# RL7005_IP_SVD register map
Vendor: Realtek
Registers are 32-bit, read-write, reset 0x0 unless marked. A register's access mark holds for its fields unless they carry their own. Offsets are from the block's base; [hi:lo] are bit positions; {n}, {i} and the like mark numbered series; <NAME> marks a mode.

## PAGE7
Base 0x40000000
0x700 REG_MACID1
  [31:0] BIT_MACID1_0 — MAC Identification Number Register for port 1
0x704 REG_MACID1_1
  [15:0] BIT_MACID1_1 — MAC Identification Number Register for port 1
0x708 REG_BSSID1
  [31:0] BIT_BSSID1_0 — Basic Station Set Identification for port 1.
0x70C REG_BSSID1_1
  [15:0] BIT_BSSID1_1 — Basic Station Set Identification for port 1.
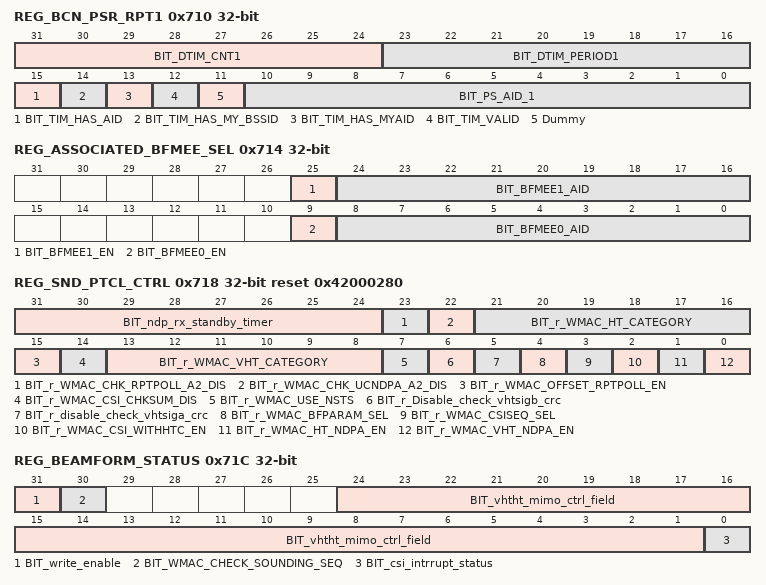
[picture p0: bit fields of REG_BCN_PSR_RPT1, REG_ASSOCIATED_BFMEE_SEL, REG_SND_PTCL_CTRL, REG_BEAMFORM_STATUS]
0x710 REG_BCN_PSR_RPT1 access per field
  [31:24] BIT_DTIM_CNT1 ro — DTIM count
  [23:16] BIT_DTIM_PERIOD1 ro — DTIM Period
  [15] BIT_TIM_HAS_AID ro — indicate BC/MC packets are buffered at the AP or transimited BSSID
  [14] BIT_TIM_HAS_MY_BSSID ro — indicate BC/MC packets are buffered at nontransmitted BSSID, sw need to check corresponding dtim count field in multiple bssid index field
  [13] BIT_TIM_HAS_MYAID ro — my aid in the virtual bitmap is set
  [12] BIT_TIM_VALID ro — when set to 1 , indicate tim report valid
  [11] Dummy rw
  [10:0] BIT_PS_AID_1 rw — AID1 for MACID1
0x714 REG_ASSOCIATED_BFMEE_SEL
  [25] BIT_BFMEE1_EN — If enabled, NDPA would be sent to beamformee1.
  [24:16] BIT_BFMEE1_AID — P_AID of the target beamformee1
  [9] BIT_BFMEE0_EN — If enabled, NDPA would be sent to beamformee0.
  [8:0] BIT_BFMEE0_AID — P_AID of the target beamformee0
0x718 REG_SND_PTCL_CTRL reset 0x42000280
  [31:24] BIT_ndp_rx_standby_timer — A timeout value for MAC to leave NDP_Rx_standby_state and go back to normal Rx mode. (unit: 2us)
  [23] BIT_r_WMAC_CHK_RPTPOLL_A2_DIS — 1: For any A1-matched BF Rpt Poll, send back VHT-CB 0: If A1-matched BF Rpt Poll's A2 fails to match the previous receiving NDPA's A2, do not send VHT-CB
  [22] BIT_r_WMAC_CHK_UCNDPA_A2_DIS — 0: If A1-matched NDPA's A2 fails to match 0x6E4 or 0x6EC, use default csi parameter 1: For any receiving A1-matched NDPA, use 0x6F4[11:0] as csi parameter
  [21:16] BIT_r_WMAC_HT_CATEGORY — csi report offset for ht mode
  [15] BIT_r_WMAC_OFFSET_RPTPOLL_EN — 1: If previous Tx pkt is BF Rpt Poll or VHT NDP, use vht csi start offset; otherwise ht csi start offset 0: If previous Tx pkt is vht rate, use vht csi start offset; otherwise ht csi start offset
  [14] BIT_r_WMAC_CSI_CHKSUM_DIS — 1:Disable check 16bit checksum value of csi report from BB 0:Enable check 16bit checksum value of csi report from BB
  [13:8] BIT_r_WMAC_VHT_CATEGORY — used as csi report offset
  [7] BIT_r_WMAC_USE_NSTS — 1: use Nsts as Nr, 0: use register value as Nr
  [6] BIT_r_Disable_check_vhtsigb_crc — 1: disable, 0: enable
  [5] BIT_r_disable_check_vhtsiga_crc — 1: disable, 0: enable
  [4] BIT_r_WMAC_BFPARAM_SEL — 1: use beamforming nc/nr/ng parameter from register 0x6F4 0: use beamforming nc/nr/ng parameter from tx report buffer
  [3] BIT_r_WMAC_CSISEQ_SEL — By which the sequence number of CSI frame is controlled 1: non-QoS SEQ number 0: counter
  [2] BIT_r_WMAC_CSI_WITHHTC_EN — Set to 1, CSI frame would carry HTC in MAC header.
  [1] BIT_r_WMAC_HT_NDPA_EN — Set to 1, MAC would inform BB of preparing to receive NDP if the received NDP Announcement MPDU is valid.
  [0] BIT_r_WMAC_VHT_NDPA_EN — Set to 1, MAC would inform BB of preparing to receive NDP if the received NDPA is valid.
0x71C REG_BEAMFORM_STATUS access per field
  [31] BIT_write_enable ro — Access flag. '0' for read. '1' for write, 0x72C[15:0] must be sett before this bit is set
  [30] BIT_WMAC_CHECK_SOUNDING_SEQ rw — Set to 1,MAC would check sounding sequence number of received CSI report and transmitted NDPA
  [24:1] BIT_vhtht_mimo_ctrl_field ro — when 'read': [24:1]: currently received VHT MIMO Control field or [16:1]: currently received HT MIMO Control field
  [0] BIT_csi_intrrupt_status ro — sounding status: '0': fail; '1': success;
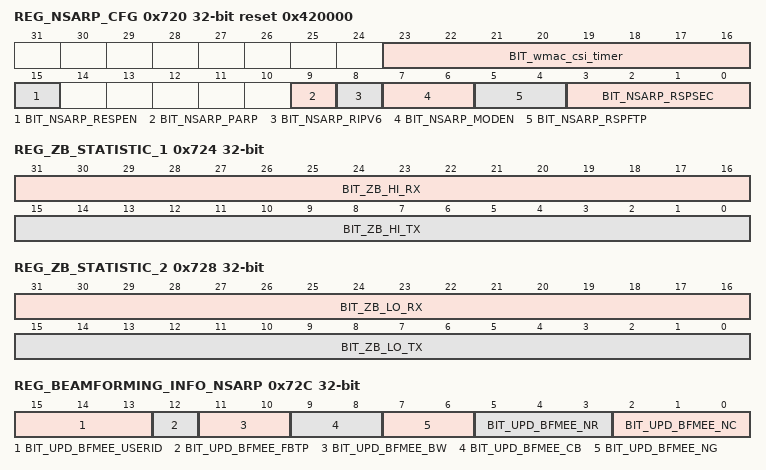
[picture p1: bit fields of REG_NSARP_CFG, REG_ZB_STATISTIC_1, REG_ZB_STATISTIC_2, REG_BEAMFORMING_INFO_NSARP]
0x720 REG_NSARP_CFG reset 0x420000
  [23:16] BIT_wmac_csi_timer — A timeout value for csi_wait_poll. (unit: 512us)
  [15] BIT_NSARP_RESPEN — NAARP parser enable
  [9] BIT_NSARP_PARP — when set to 1, reject ARP
  [8] BIT_NSARP_RIPV6 — when set to 1, reject IPV6
  [7:6] BIT_NSARP_MODEN — r_WMAC_NSARP_MODEN[0]: when set to 1, enable arp request; r_WMAC_NSARP_MODEN[1]: when set to 1, enable ipv6 request;
  [5:4] BIT_NSARP_RSPFTP — used to select Response_type and TID
  [3:0] BIT_NSARP_RSPSEC — select response packet security type
0x724 REG_ZB_STATISTIC_1 ro
  [31:16] BIT_ZB_HI_RX — for statistic
  [15:0] BIT_ZB_HI_TX
0x728 REG_ZB_STATISTIC_2 ro
  [31:16] BIT_ZB_LO_RX — for statistic
  [15:0] BIT_ZB_LO_TX
0x72C REG_BEAMFORMING_INFO_NSARP
  [15:13] BIT_UPD_BFMEE_USERID — Select BFMEE User ID
  [12] BIT_UPD_BFMEE_FBTP — Feedback Type(B11) of VHT MIMO Control field, HT is no used
  [11:10] BIT_UPD_BFMEE_BW — Channel Width of VHT MIMO control field (B7-6) and (B4) when HT mode
  [9:8] BIT_UPD_BFMEE_CB — Codebook Information of MIMO control field [8] for VHT (B10) and (B10-9) when HT mode
  [7:6] BIT_UPD_BFMEE_NG — Grouping of MIMO control field [7:6] for VHT (B9-8) and (B6-5) when HT mode
  [5:3] BIT_UPD_BFMEE_NR — Nr Index of MIMO control field [5:3] for VHT (B5-3) ,[4:3] for HT mode (B3-2)
  [2:0] BIT_UPD_BFMEE_NC — Nc Index of MIMO control field [2:0] for VHT (B2-0) , [1:0] for HT mode (B1-0)
{0x730+4i} REG_IPV6_{i} (i=0..3)
  [31:0] BIT_IPV6_MYIPAD_{i}
0x740 REG_ZB_COEX_TABLE_1
  [31:0] BIT_ZB_COEX_TABLE_1 — coexistence table between WLAN and Zigbee, selected by BIT_COEX_TABLE_SEL = 0
0x744 REG_ZB_COEX_TABLE_2
  [31:0] BIT_ZB_COEX_TABLE_2 — coexistence table between WLAN and Zigbee, selected by BIT_COEX_TABLE_SEL = 1
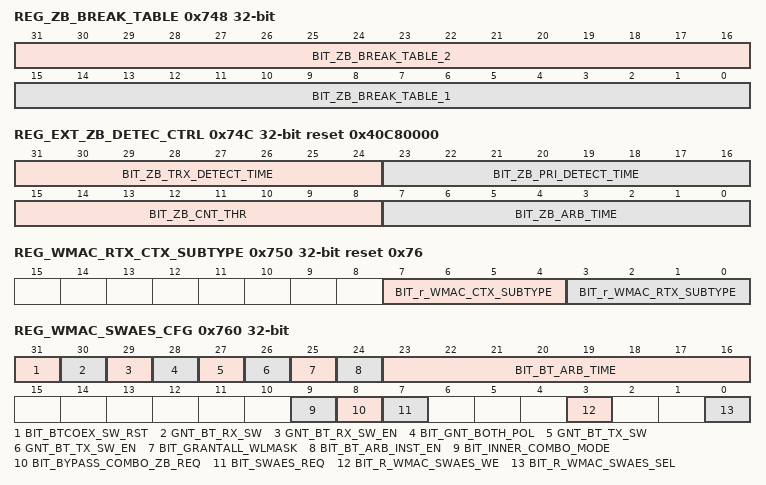
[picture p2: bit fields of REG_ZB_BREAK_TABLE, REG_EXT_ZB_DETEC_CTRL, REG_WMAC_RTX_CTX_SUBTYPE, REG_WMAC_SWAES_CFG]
0x748 REG_ZB_BREAK_TABLE
  [31:16] BIT_ZB_BREAK_TABLE_2 — Table used to break ZB activity, when new WLAN request is coming and ZB is on transmitting or receiving
  [15:0] BIT_ZB_BREAK_TABLE_1 — Table used to break WLAN activity, when new ZB request is coming and WLAN is on transmitting or receiving
0x74C REG_EXT_ZB_DETEC_CTRL reset 0x40C80000
  [31:24] BIT_ZB_TRX_DETECT_TIME — Valid if BIT_ZIGBEE_MODE = 1 & BIT_EXT_ZIGBEE_MODE = 0 (external mode, directional PRIORITY) After ZB_PRI_DETECT_TIME duration, if ZB_PRIORITY is low or goes low during ZB_TRX_INIT_DETECT_TIME, Zigbee will receive packets; otherwise, if ZG_PRIORITY is high or goes high, ZB will TX data. Unit 1us.
  [23:16] BIT_ZB_PRI_DETECT_TIME — Valid if BIT_ZIGBEE_MODE = 1 & BIT_EXT_ZIGBEE_MODE = 0 (external mode, directional PRIORITY) After ZB_REQUEST asserting, if ZG_PRIORITY is asserted within this ZB_PRI_DETECT_TIME duration, ZG will initiate high priority activities; otherwise, if ZB_PRIORITY is not asserted within this duration, it would be low priority activities. Units 1us. (0-255us)
  [15:8] BIT_ZB_CNT_THR — ZB count threshold, unit: us
  [7:0] BIT_ZB_ARB_TIME — 8 bit timer register : Arbitration window of ZB trx request (unit: us)
0x750 REG_WMAC_RTX_CTX_SUBTYPE reset 0x76
  [7:4] BIT_r_WMAC_CTX_SUBTYPE, [3:0] BIT_r_WMAC_RTX_SUBTYPE
{0x750+4i} REG_WMAC_RTX_SWAES_RD_{i} ro (i=1..3)
  [31:0] wmac_swaes_rd_{i-1}
0x760 REG_WMAC_SWAES_CFG access per field
  [31] BIT_BTCOEX_SW_RST rw
  [30] GNT_BT_RX_SW rw — SW control GNT_BT_RX
  [29] GNT_BT_RX_SW_EN rw — SW control GNT_BT_RX enable
  [28] BIT_GNT_BOTH_POL rw — grant both choose GNT_BT polarity: 0 : deassert GNT_BT signal as PTA grant both WiFI and BT. 1 : assert GNT_BT signal as PTA grant both WiFi and BT.
  [27] GNT_BT_TX_SW rw — SW control GNT_BT_TX
  [26] GNT_BT_TX_SW_EN rw — SW control GNT_BT_TX enable
  [25] BIT_GRANTALL_WLMASK rw — 0: WLAN_ACT to BT is always 0
  [24] BIT_BT_ARB_INST_EN rw — 1: enable GNT_BT_BYPASS_PRIORITY 0 : disable
  [23:16] BIT_BT_ARB_TIME rw — 8 bit timer register : Arbitration window of bt trx request ( in the unit of us)
  [9] BIT_INNER_COMBO_MODE rw — 1: RTK combo IP parser zb_request or bt_request,zb_request will use wl-zb coex table co-work with BIT_BYPASS_COMBO_ZB_REQ = 0
  [8] BIT_BYPASS_COMBO_ZB_REQ rw — 1: ignore zb flag from RTK combo IP 0: distinguish zb_request and bt_request from RTK combo IP
  [7] BIT_SWAES_REQ ro — software aes engine request polling
  [3] BIT_R_WMAC_SWAES_WE rw — Write enable of register ro_WMAC_SWAES_RD
  [0] BIT_R_WMAC_SWAES_SEL rw — When R_WMAC_SWAES_SEL =1,the content of register 0750-075F used to be aes engine data in or data out . When R_WMAC_SWAES_SEL =0, the content of register 0754-075F used to be aes engine security key
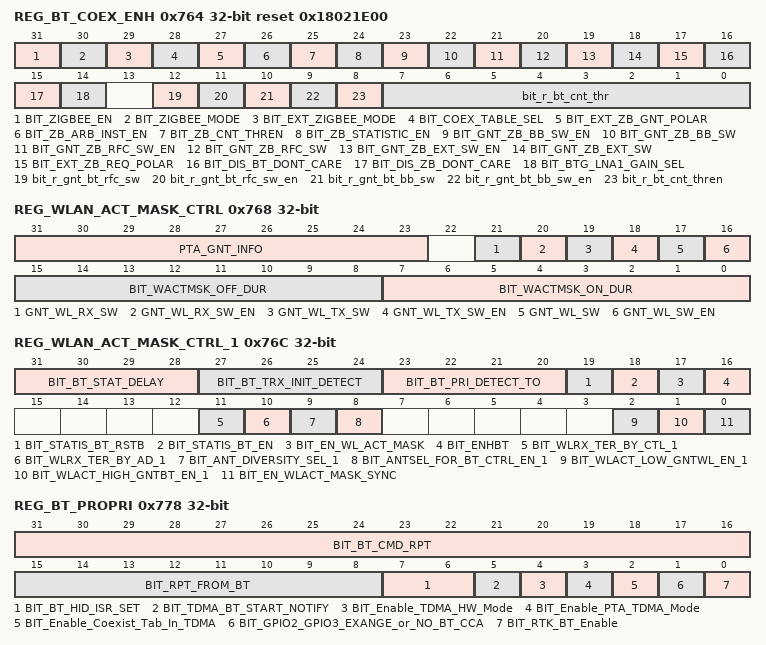
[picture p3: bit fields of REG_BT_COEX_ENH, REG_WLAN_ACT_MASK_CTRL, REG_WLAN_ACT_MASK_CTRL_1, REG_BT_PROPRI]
0x764 REG_BT_COEX_ENH reset 0x18021E00
  [31] BIT_ZIGBEE_EN — Enable ZigBee function
  [30] BIT_ZIGBEE_MODE — 0: SOC 1: external
  [29] BIT_EXT_ZIGBEE_MODE — The mode of external ZigBee 1: static PRIORITY 0: directional PRIORITY
  [28] BIT_COEX_TABLE_SEL — Select coexistence table for WLAN & ZB 0: BIT_COEX_TABLE_WL_ZB_1 1: BIT_COEX_TABLE_WL_ZB_2
  [27] BIT_EXT_ZB_GNT_POLAR — Select the polar of ZB_GRANT, for extarnal ZB 0: low active 1: high active
  [26] BIT_ZB_ARB_INST_EN — 1: enable the time limit of ZigBee request (zb_pri | zb_rx | zb_tx), PTA is valid during ( <=BIT_ZB_ARB_TIME) 0: disable Co-work with BIT_ZB_ARB_TIME
  [25] BIT_ZB_CNT_THREN — ZB count threshold enable, for statistics co-work with BIT_ZB_CNT_THR
  [24] BIT_ZB_STATISTIC_EN — enable statistic of ZB
  [23] BIT_GNT_ZB_BB_SW_EN — Enable SW control gnt_zb_bb
  [22] BIT_GNT_ZB_BB_SW — SW value
  [21] BIT_GNT_ZB_RFC_SW_EN — Enable SW control gnt_zb_rfc
  [20] BIT_GNT_ZB_RFC_SW — SW value
  [19] BIT_GNT_ZB_EXT_SW_EN — Enable SW control gnt_zb_o of external ZigBee
  [18] BIT_GNT_ZB_EXT_SW — SW value, external ZigBee
  [17] BIT_EXT_ZB_REQ_POLAR — Select the polar of ZB_REQUEST, for static mode external ZB 0: low active 1: high active
  [16] BIT_DIS_BT_DONT_CARE — 1: break table of BT & WL can be all "1" 0: break table of BT & WL cannot be all "1"
  [15] BIT_DIS_ZB_DONT_CARE — 1: break table of ZB & WL can be all "1" 0: break table of ZB & WL cannot be all "1"
  [14] BIT_BTG_LNA1_GAIN_SEL — control by Driver 0: mask for WL 1: original BTG
  [12] bit_r_gnt_bt_rfc_sw — SW control BT RF
  [11] bit_r_gnt_bt_rfc_sw_en — SW control BT RF enable
  [10] bit_r_gnt_bt_bb_sw — SW control BT baseband
  [9] bit_r_gnt_bt_bb_sw_en — SW control BT baseband enable
  [8] bit_r_bt_cnt_thren — BT count threshold enable
  [7:0] bit_r_bt_cnt_thr — BT count threshold
0x768 REG_WLAN_ACT_MASK_CTRL access per field
  [31:23] PTA_GNT_INFO ro — [0]: gnt_wl [1]: gnt_bt_bb [2]: gnt_bt_rfc [3]: gnt_zb_bb [4]: gnt_zb_rfc [5]: gnt_wl_tx [6]: gnt_wl_rx [7]: gnt_bt_tx [8]: gnt_bt_rx
  [21] GNT_WL_RX_SW rw — SW control GNT_WL_RX
  [20] GNT_WL_RX_SW_EN rw — SW control GNT_WL_RX enable
  [19] GNT_WL_TX_SW rw — SW control GNT_WL_TX
  [18] GNT_WL_TX_SW_EN rw — SW control GNT_WL_TX enable
  [17] GNT_WL_SW rw — SW control GNT_WL
  [16] GNT_WL_SW_EN rw — SW control GNT_WL enable
  [15:8] BIT_WACTMSK_OFF_DUR rw — WLAN will reserve channel for BT during MASK OFF duration. Unit 0.625ms
  [7:0] BIT_WACTMSK_ON_DUR rw — WLAN can block BT during MASK On duration. Unit 0.625ms
0x76C REG_WLAN_ACT_MASK_CTRL_1
  [31:28] BIT_BT_STAT_DELAY — For CSR, BT_PRI and BT_STAT go high form low at the same time. Thus, BT_STAT need delay BT_STAT_DELAY time to trigger hardware. Unit: 1us
  [27:24] BIT_BT_TRX_INIT_DETECT — After BT_PRI asserting for BT_TRX_INIT_DETECT us, if BT_STAT is low, then BT will receive packets; otherwise, if BT goes high, BT will TX data. Unit 4us.
  [23:20] BIT_BT_PRI_DETECT_TO — After BT_PRI asserting, if BT_STAT is asserted within this TO duration, BT will initiate high priority activities; otherwise, if BT_STAT is not asserted within this duration, it would be low priority activities. Units 1us.
  [19] BIT_STATIS_BT_RSTB — clear BT static info
  [18] BIT_STATIS_BT_EN — When this bit is set, the BT_ACT_STATISTICS counters starts counting
  [17] BIT_EN_WL_ACT_MASK — Enable WLAN_ACT Mask Function (related to 0x768h-0x76Dh)
  [16] BIT_ENHBT — Enable Enhanced BT Interface (we suggest to use with BT mode 2)
  [11] BIT_WLRX_TER_BY_CTL_1 — When wlan receive a control packet without fit address, whether the signal indicating wlan rx can be terminated as soon as the address check finish is not only controlled by r_WLRX_TER_BY_AD, but also should be refereed to this bit. 1: enable; 0: disable
  [10] BIT_WLRX_TER_BY_AD_1 — When wlan receive the packet without fit address, the signal indicating wlan rx can be terminated as soon as the address check finish. This feature can be enabled by this bit. 1: en
  [9] BIT_ANT_DIVERSITY_SEL_1 — Antenna diversity for 2 antenna mode: MAC_ANT_SEL = GNT_BT ^ ANT_DIVERDITY_SEL
  [8] BIT_ANTSEL_FOR_BT_CTRL_EN_1 — Enable the control of antenna selection through GNT_BT: GNT_BT=1: ANT_SEL for BT device; GNT_BT=0: ANT_SEL for WL device.
  [2] BIT_WLACT_LOW_GNTWL_EN_1 — When WLACT_LOW_GNTWL_EN = 1, the TRX of WLAN are blocked according to the BTCOEX table arbitration during MASK OFF duration. WLACT_LOW_GNTWL_EN = 0, the TRX of WLAN are paused during MASK OFF duration..
  [1] BIT_WLACT_HIGH_GNTBT_EN_1 — When WLACT_HIGH_GNTBT_EN = 1, the TRX of WLAN are blocked according to the BTCOEX table arbitration during MASK ON duration. When WLACT_HIGH_ GNTBT_EN = 0, the TRX of WLAN are not paused during MASK OFF duration.
  [0] BIT_EN_WLACT_MASK_SYNC — When NAV update is beyond this value, then NAV update is aborted. When this field is 0x00, NAV_UPPER function is disable. The unit is 128us.
0x770 REG_BT_ENHANCED_CTRL0 ro
  [31:0] BIT_STATIS_BT_31_0
0x774 REG_BT_ENHANCED_CTRL1 ro
  [31:0] BIT_STATIS_BT_63_32
0x778 REG_BT_PROPRI access per field
  [31:16] BIT_BT_CMD_RPT ro
  [15:8] BIT_RPT_FROM_BT ro
  [7:6] BIT_BT_HID_ISR_SET rw — When EN_BT_PROFILE_OR_HID is set "1", hardware also need to check this value to trigger an interrupt. 0: default, TX and RX 1: TX 2: RX 3: Reserved
  [5] BIT_TDMA_BT_START_NOTIFY rw — When the control of TDMA mode is firmware and firmware also receive signal that NULL packet for BT had sent, firmware can fill this bit to notify HW PTA to pull WLAN_ACT to low and the interval is Tbt
  [4] BIT_Enable_TDMA_HW_Mode rw — 0: default, PTA TDMA mode is hardware mode. 1: enable firmware mode.
  [3] BIT_Enable_PTA_TDMA_Mode rw — 0: default, disable PTA TDMA mode 1: enable TDMA mode: a. WLAN_ACT default is high. b. Hardware mode: When NULL packet for BT had sent, hardware will notify PTA to start TDMA mode. Firmware mode: When NULL packet for BT had sent, hardware will trigger an interrupt to notify firmware. Then, firmware need to set TDMA_BT_START_NOTIFY to notify PTA to start TDMA mode.
  [2] BIT_Enable_Coexist_Tab_In_TDMA rw — 0: default, no matter which WLAN_ACT is high or low, PTA doesn't execute co-exist table scheme 1: enable, When WLAN_ACT is high, PTA execute xo-exist table scheme
  [1] BIT_GPIO2_GPIO3_EXANGE_or_NO_BT_CCA rw — Enable GPIO2 and GPIO3 exchange. (Note: need to enable mode2 and enhance 3 wire) If Enable RTK BT mode, set this bit to 1 to disable granting to BT device when arbitration
  [0] BIT_RTK_BT_Enable rw — Enable RTK BT mode
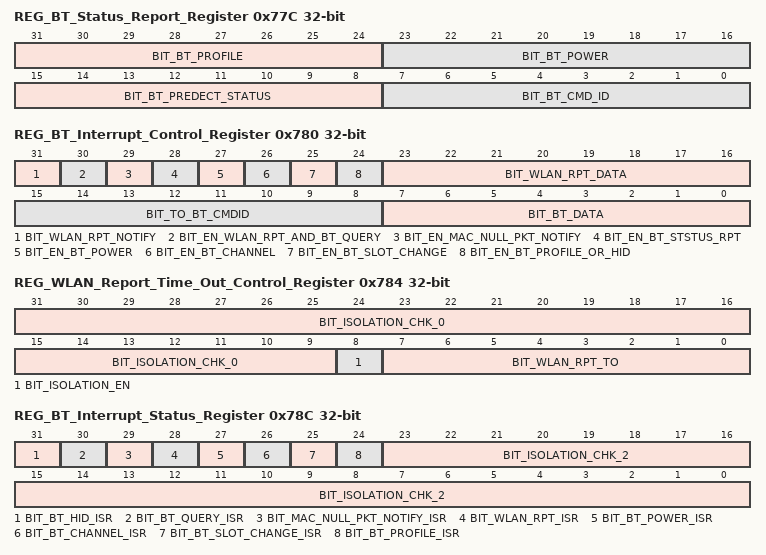
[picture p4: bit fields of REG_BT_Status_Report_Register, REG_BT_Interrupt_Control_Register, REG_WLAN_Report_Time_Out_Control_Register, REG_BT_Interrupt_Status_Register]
0x77C REG_BT_Status_Report_Register ro
  [31:24] BIT_BT_PROFILE — When WLAN received CMD_ID 0x3, it will recorder to this.
  [23:16] BIT_BT_POWER — When WLAN received CMD_ID 0x2, it will recorder to this
  [15:8] BIT_BT_PREDECT_STATUS — When WLAN received CMD_ID 0x0, it will recorder to this
  [7:0] BIT_BT_CMD_ID — command information from BT
0x780 REG_BT_Interrupt_Control_Register access per field
  [31] BIT_WLAN_RPT_NOTIFY rw — When firmware had prepared packet to send to BT, it need to set this bit to notify hardware that it can transmit. 0: There isn't a valid packet in register" WLAN_RPT_ PKT". 1: There is a valid packet in register" WLAN_RPT_ PKT".
  [30] BIT_EN_WLAN_RPT_AND_BT_QUERY rw — Enable two interrupt: 1) PTA sent the report packet successfully 2) PTA sent a query packet 0: Disable 1: Enable
  [29] BIT_EN_MAC_NULL_PKT_NOTIFY rw — When MAC had sent NULL packet for BT and firmware also set nav_for_bt bit, hardware triggers an interrupt to notify firmware. 0: Disable 1: Enable
  [28] BIT_EN_BT_STSTUS_RPT rw — When WLAN receive cmd_id "0", hardware trigger an interrupt to notify firmware. 0: Disable 1: Enable
  [27] BIT_EN_BT_POWER rw — When WLAN received the packet including BT Power and check register "BT_STATUS_RPT", if data contents aren't the same, hardware can trigger an interrupt to notify firmware. 0: Disable 1: Enable
  [26] BIT_EN_BT_CHANNEL rw — When WLAN received the packet including BT channel number, hardware can trigger an interrupt to notify firmware. 0: Disable 1: Enable
  [25] BIT_EN_BT_SLOT_CHANGE rw — When WLAN received the packet including that BT had multi-slots, hardware can trigger an interrupt to notify firmware. 0: Disable 1: Enable
  [24] BIT_EN_BT_PROFILE_OR_HID rw — Enable two interrupt 1) When WLAN received the packet including that WLAN specific profile and check register "BT_STATUS_RPT", if data contents aren't the same, hardware can trigger an interrupt to notify firmware. 2) When WLAN received the report packet including HID information, hardware will trigger an interrupt to notify firmware. 0: Disable 1: Enable
  [23:16] BIT_WLAN_RPT_DATA rw — Data contents, When the report packet had sent, hardware will clear this register.
  [15:8] BIT_TO_BT_CMDID rw — Command id: 0x80~FF
  [7:0] BIT_BT_DATA ro — When WLAN received the packet BT sent, hardware will place data to this register in addition to CMD_ID 0x0 ~ 0x3.
0x784 REG_WLAN_Report_Time_Out_Control_Register
  [31:9] BIT_ISOLATION_CHK_0 — 0: leave PTA 1: enter PTA
  [8] BIT_ISOLATION_EN — Isolation table enable bit. 0: disable 1: enable
  [7:0] BIT_WLAN_RPT_TO — When WLANＨW received query packet, HW timer counts. If timer equals to WLAN_RPT_TO and HW can"t send packet, it will give up query packet at this time. When BT sent another query packet, WLAN HW need to send the previous packet and it shouldn't trigger an interrupt to firmware. Unit: 4us.
0x788 REG_BT_Isolation_Table_Register_Register_1
  [31:0] BIT_ISOLATION_CHK_1 — 0: leave PTA 1: enter PTA
0x78C REG_BT_Interrupt_Status_Register access per field
  [31] BIT_BT_HID_ISR ro — When WLAN received the report packet including HID information, hardware will trigger an interrupt to notify firmware
  [30] BIT_BT_QUERY_ISR ro — When WLAN received a query packet, hardware triggers an interrupt to notify firmware
  [29] BIT_MAC_NULL_PKT_NOTIFY_ISR ro — When MAC had sent NULL packet for BT and firmware also set nav_for_bt bit, hardware triggers an interrupt to notify firmware
  [28] BIT_WLAN_RPT_ISR ro — When PTA sent the report packet successfully, hardware triggers an interrupt to notify firmware.
  [27] BIT_BT_POWER_ISR ro — When WLAN received the packet including BT Power and check register "BT_STATUS_RPT", if data contents aren't the same, hardware can trigger an interrupt to notify firmware
  [26] BIT_BT_CHANNEL_ISR ro — When WLAN received the packet including BT channel number, hardware can trigger an interrupt to notify firmware.
  [25] BIT_BT_SLOT_CHANGE_ISR ro — When WLAN received the packet including that BT had multi-slots, hardware can trigger an interrupt to notify firmware
  [24] BIT_BT_PROFILE_ISR ro — When WLAN received the packet including that WLAN specific profile and check register "BT_STATUS_RPT", if data contents aren't the same, hardware can trigger an interrupt to notify firmware.
  [23:0] BIT_ISOLATION_CHK_2 rw — 0: leave PTA 1: enter PTA
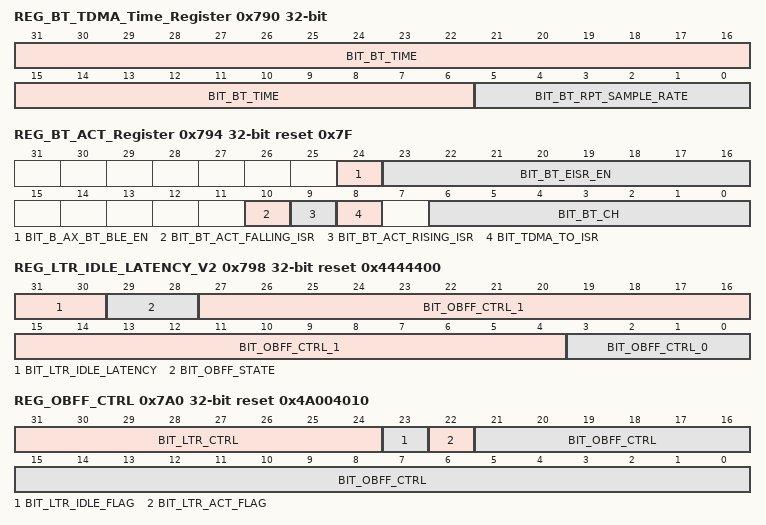
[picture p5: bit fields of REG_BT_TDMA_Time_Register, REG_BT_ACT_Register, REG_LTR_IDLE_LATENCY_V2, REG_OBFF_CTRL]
0x790 REG_BT_TDMA_Time_Register
  [31:6] BIT_BT_TIME — The time is that WLAN_ACT is low. Unit: us
  [5:0] BIT_BT_RPT_SAMPLE_RATE — When wifi detected the raising edge of BT report packet, wifi need to counter BT_RPT_SAMPLE_RATE. Then hw could detect which is high or low. Uint: 20 ns
0x794 REG_BT_ACT_Register access per field reset 0x7F
  [24] BIT_B_AX_BT_BLE_EN rw — Decide the GNT_BT_TX / RX 0: GNT_BT_TX = GNT_BT & BT_TX ; GNT_BT_RX = GNT_BT & BT_RX 1: GNT_BT_TX = GNT_BT & (BT_TX | BT_BLE) ; GNT_BT_RX = GNT_BT & (BT_RX | BT_BLE)
  [23:16] BIT_BT_EISR_EN rw — BT eisr enable
  [10] BIT_BT_ACT_FALLING_ISR ro — When BT_ACT signal is falling edge, it will trigger an interrupt.
  [9] BIT_BT_ACT_RISING_ISR ro — When BT_ACT signal is raising edge, it will trigger an interrupt
  [8] BIT_TDMA_TO_ISR ro — When BT_TIME expired, it will trigger an interrupt.
  [6:0] BIT_BT_CH ro — When hardware receive cm_id "1", it will recorder to this.
0x798 REG_LTR_IDLE_LATENCY_V2 access per field reset 0x4444400
  [31:30] BIT_LTR_IDLE_LATENCY rw — LTR idle latency.
  [29:28] BIT_OBFF_STATE ro
  [27:4] BIT_OBFF_CTRL_1 rw
  [3:0] BIT_OBFF_CTRL_0 ro
0x79C REG_LTR_ACTIVE_LATENCY_V2 reset 0x2030405
  [31:0] BIT_LTR_ACTIVE_LATENCY — LTR Active latency.
0x7A0 REG_OBFF_CTRL access per field reset 0x4A004010
  [31:24] BIT_LTR_CTRL rw, [23] BIT_LTR_IDLE_FLAG ro, [22] BIT_LTR_ACT_FLAG ro, [21:0] BIT_OBFF_CTRL rw
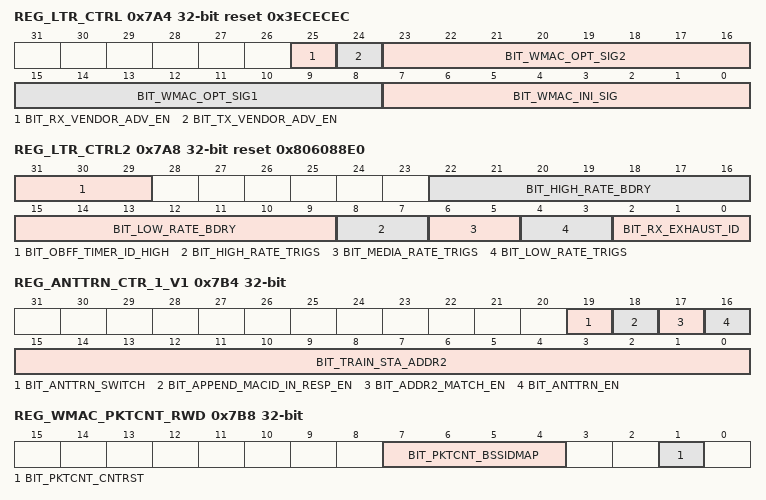
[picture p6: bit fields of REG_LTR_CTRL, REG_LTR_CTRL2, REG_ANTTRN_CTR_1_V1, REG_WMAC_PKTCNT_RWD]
0x7A4 REG_LTR_CTRL reset 0x3ECECEC
  [25] BIT_RX_VENDOR_ADV_EN — when set, rx vendor adv function is true
  [24] BIT_TX_VENDOR_ADV_EN — when set, tx vendor adv function is true
  [23:16] BIT_WMAC_OPT_SIG2 — For rx ofdm ppdu lsig signal filed check when rx vendor adv is true
  [15:8] BIT_WMAC_OPT_SIG1 — For rx ofdm ppdu lsig signal filed check when rx vendor adv is true
  [7:0] BIT_WMAC_INI_SIG — For rx ofdm ppdu lsig signal filed check when rx vendor adv is true
0x7A8 REG_LTR_CTRL2 reset 0x806088E0
  [31:29] BIT_OBFF_TIMER_ID_HIGH — When media rate rx packet in , delay rx dma timeout value index. 0: no delay,1: 12.8us; 2: 102.4us; 3: 204.8us; 4: 819.2 us; 5: 1.638ms; 6: 52ms; 7: always block until obff or cpu active window
  [22:16] BIT_HIGH_RATE_BDRY — High, media, low rate boundary
  [15:9] BIT_LOW_RATE_BDRY — High, media, low rate boundary
  [8:7] BIT_HIGH_RATE_TRIGS — High rate rx ltr trigger point select: 0 plcp ready;1: rx a1 latch OK; 2: fcs ready.
  [6:5] BIT_MEDIA_RATE_TRIGS — Media rate rx ltr trigger point select: 0 plcp ready;1: rx a1 latch OK; 2: fcs ready.
  [4:3] BIT_LOW_RATE_TRIGS — Low rate rx ltr trigger point select: 0 plcp ready;1: rx a1 latch OK; 2: fcs ready.
  [2:0] BIT_RX_EXHAUST_ID — When rx page less than this threshold, release obff block rx.
0x7B0 REG_ANTTRN_CTR_V1
  [31:0] BIT_TRAIN_STA_ADDR1 — The Address of the trained station. Only available when ADDR2_MATCH_EN = 1
0x7B4 REG_ANTTRN_CTR_1_V1
  [19] BIT_ANTTRN_SWITCH — Smart antenna use address cam or port register to search A2. 0:Use address cam 1:Use port register
  [18] BIT_APPEND_MACID_IN_RESP_EN — Whether to append MACID in the rx descriptor of rx response packet
  [17] BIT_ADDR2_MATCH_EN — Enable the comparison of ADDR2 for the rx packet..
  [16] BIT_ANTTRN_EN — Enable the antenna training function
  [15:0] BIT_TRAIN_STA_ADDR2 — The Address of the trained station. Only available when ADDR2_MATCH_EN = 1
0x7B8 REG_WMAC_PKTCNT_RWD ro
  [7:4] BIT_PKTCNT_BSSIDMAP — To decide this counter is for which MBSSID (16組), default : 0 for counter 0 1 for counter 1 2 for counter 2 3 for counter 3 4 for counter 4 5 for counter 5 6 for counter 6 7 for counter 7
  [1] BIT_PKTCNT_CNTRST — Write 1 to reset Counter after DRV read all counters , DRV set this bit and HW return 0 after reset
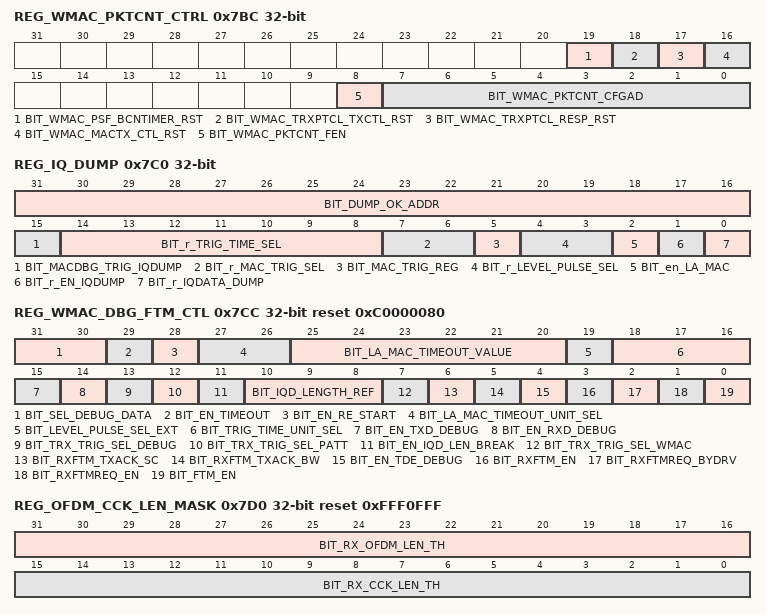
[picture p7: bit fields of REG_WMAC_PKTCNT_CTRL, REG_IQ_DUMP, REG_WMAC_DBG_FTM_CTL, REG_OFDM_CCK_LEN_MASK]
0x7BC REG_WMAC_PKTCNT_CTRL access per field
  [19] BIT_WMAC_PSF_BCNTIMER_RST wo — write pluse to reset fsm of wmac_psf_bcntimer
  [18] BIT_WMAC_TRXPTCL_TXCTL_RST wo — write pluse to reset fsm of wmac_trxptcl_txctl
  [17] BIT_WMAC_TRXPTCL_RESP_RST wo — write pluse to reset fsm of wmac_ptrxptcl_resp
  [16] BIT_WMAC_MACTX_CTL_RST wo — write pluse to reset fsm of ppdu control in mactx_ctl
  [8] BIT_WMAC_PKTCNT_FEN rw — Packet counter function enable
  [7:0] BIT_WMAC_PKTCNT_CFGAD rw — Packet counter configure register read/write address
0x7C0 REG_IQ_DUMP access per field
  [31:16] BIT_DUMP_OK_ADDR ro — [31] : dump signal addr has round up [30:16] : dump finish addr in txpktbuffer
  [15] BIT_MACDBG_TRIG_IQDUMP rw — Enable dump bb ADC signal trigger from MAC debug port which controled by r_LEVEL_PULSE_SEL.
  [14:8] BIT_r_TRIG_TIME_SEL rw — dump ok time to finish dump signal(unit is 1us)
  [7:6] BIT_r_MAC_TRIG_SEL rw — dump bb ADC sel mac strigger even 2'b00 : rxpkt ok trig dump ok 2'b01 : rxpkt_fauil trig dump ok 2'b10 : rxpkt cca rise edge to trig dump ok
  [5] BIT_MAC_TRIG_REG rw — dump bb ADC sel mac strigger even write this reg to 1 to trig dump finish
  [4:3] BIT_r_LEVEL_PULSE_SEL rw — if dump bb ADC signal : [3] for sel mac trigger event if dump mac dbg signal [4:3] : 2'b00 : level signal match [4:3] : 2'b01 : posedge match [4:3] : 2'b10 : negdge match
  [2] BIT_en_LA_MAC rw — enable dump mac dbg signal
  [1] BIT_r_EN_IQDUMP rw — enable dump bb ADC signal
  [0] BIT_r_IQDATA_DUMP rw — enable data dump for txpktbuffer high 64K
0x7C4 REG_MASK_LA_MAC
  [31:0] BIT_MASK_LA_MAC — used for mask one or more bits of debug port
0x7C8 REG_MATCH_REF_MAC
  [31:0] BIT_MATCH_REF_MAC — used for compare with debug port
0x7CC REG_WMAC_DBG_FTM_CTL reset 0xC0000080
  [31:30] BIT_SEL_DEBUG_DATA — 11: data write to sram 10: data after sync_fifo 01: input data (TXD/RXD/IQ_DMA_DATA from BB) 00: RSVD
  [29] BIT_EN_TIMEOUT — Set this bit to 1 to reset mdpk read pointer
  [28] BIT_EN_RE_START — Before setting 0x7C0[1:0] =2'b11, set this bit to 1 to enable MDPK access mode
  [27:26] BIT_LA_MAC_TIMEOUT_UNIT_SEL — LA mode triggered by mac debug port timeout value unit selection. 2'b00: 1us, 2'b01:32us, 2'b10: 1ms, 2'b11:RSVD
  [25:20] BIT_LA_MAC_TIMEOUT_VALUE — LA mode triggered by mac debug port timeout value, available with non-zero value.
  [19] BIT_LEVEL_PULSE_SEL_EXT — LA mode triggered by mac debug port timeout event
  [18:16] BIT_TRIG_TIME_UNIT_SEL — Select trigger time unit of 0x7C0[14:8]. 3'b000 : 1us , 3'b001 : 2us , 3'b010 : 4us , 3'b011 : 8us , 3'b100 : 16us , 3'b101 : 32us , 3'b110 : 64us, 3'b111 : RSV
  [15] BIT_EN_TXD_DEBUG — LA MODE function. enable mactx debug mode
  [14] BIT_EN_RXD_DEBUG — LA MODE function. enable macrx debug mode
  [13] BIT_TRX_TRIG_SEL_DEBUG — LA MODE function. *1: select trig_stop signals from debug port, in MACTX/MACRX mode
  [12] BIT_TRX_TRIG_SEL_PATT — LA MODE function. *1: select trig_stop signals from pattern match (see 0x17F0~0x17FC), in MACTX/MACRX mode
  [11] BIT_EN_IQD_LEN_BREAK — LA MODE function. *1: after "trig_stop" signal asserted, if the iqdata's length over the BIT_IQD_LENGTH_REF, finish the iqdump process *0: only used TRIG_TIME finish the iqdump process
  [10:8] BIT_IQD_LENGTH_REF — LA MODE function. Valid when BIT_EN_IQD_LEN_BREAK = 1 Used to finish IQDUMP, unit is (8KB + 1bit)
  [7] BIT_TRX_TRIG_SEL_WMAC — LA MODE function. *1: select trig_stop signals from mactx or macrx, in MACTX/MACRX mode
  [6] BIT_RXFTM_TXACK_SC — When HW receive FTM pkt, HW will use RX FTM BW as response ACK TXBW.
  [5] BIT_RXFTM_TXACK_BW — When HW receive FTM pkt, HW will use RX FTM SC as response ACK TXSC.
  [4] BIT_EN_TDE_DEBUG — LA MODE function. enable txdma debug mode
  [3] BIT_RXFTM_EN — If BIT_FTM_TYPE = 1 && BIT_RXFTM_EN=1, HW will parsing rx packet, to find FTM request frame.
  [2] BIT_RXFTMREQ_BYDRV — If set this bit to 1,Rx FTMREQ/FTM can be receive into rxpktbuffer.
  [1] BIT_RXFTMREQ_EN — If BIT_FTM_TYPE = 1 && BIT_RXFTMREQ_EN=1, HW will parsing rx packet, to find FTM request frame.
  [0] BIT_FTM_EN — Fine timing measurement function; 0: Disable 1:enable
0x7D0 REG_OFDM_CCK_LEN_MASK reset 0xFFF0FFF
  [31:16] BIT_RX_OFDM_LEN_TH — rx ofdm len over this len to drop pkt(not for ht/vht)
  [15:0] BIT_RX_CCK_LEN_TH — rx cck len over this length to drop pkt
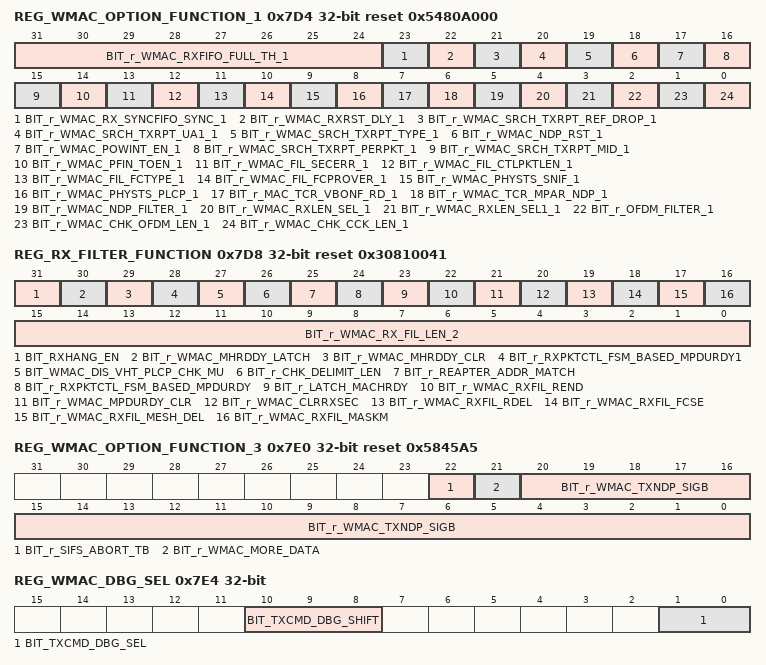
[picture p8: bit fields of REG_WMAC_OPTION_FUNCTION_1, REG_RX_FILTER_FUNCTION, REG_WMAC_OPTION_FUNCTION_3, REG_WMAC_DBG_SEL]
0x7D4 REG_WMAC_OPTION_FUNCTION_1 reset 0x5480A000
  [31:24] BIT_r_WMAC_RXFIFO_FULL_TH_1 — csi report mac pause bb almost full threshold
  [23] BIT_r_WMAC_RX_SYNCFIFO_SYNC_1
  [22] BIT_r_WMAC_RXRST_DLY_1 — when this bit is set 1, rxrst pulse lasts for 20 cycle of MAC clock, when this bit is set 0, rxrst pulse lasts for 10 cycle of MAC clock,
  [21] BIT_r_WMAC_SRCH_TXRPT_REF_DROP_1 — when this bit is set 1, reference macid drop information when macid search
  [20] BIT_r_WMAC_SRCH_TXRPT_UA1_1 — when this bit is set 1, use tx A1 to search txrpt when rx ack/cts, when BIT_r_WMAC_SRCH_TXRPT_TYPE is set 0, BIT_r_WMAC_SRCH_TXRPT_UA1 should be set 1
  [19] BIT_r_WMAC_SRCH_TXRPT_TYPE_1 — for rx ack/cts pkt not to search txrpt buffer macid
  [18] BIT_r_WMAC_NDP_RST_1 — rx pkt is ndp to clr macrx_active
  [17] BIT_r_WMAC_POWINT_EN_1 — enable rx pkt fc column power bit int for FISR
  [16] BIT_r_WMAC_SRCH_TXRPT_PERPKT_1 — enable search txrpt buffer for macid every pkt
  [15] BIT_r_WMAC_SRCH_TXRPT_MID_1 — enable search txrpt buffer for macid
  [14] BIT_r_WMAC_PFIN_TOEN_1 — rx fifo fsm flush state timeout to error stage
  [13] BIT_r_WMAC_FIL_SECERR_1 — sec len error drop(sec len is zero)
  [12] BIT_r_WMAC_FIL_CTLPKTLEN_1 — drop the rx pkt if the rx ctrl pkt len large than r_WMAC_RX_FIL_LEN
  [11] BIT_r_WMAC_FIL_FCTYPE_1 — drop the ofdm pkt if the rx ofdm leg pkt fc type is 2'b11
  [10] BIT_r_WMAC_FIL_FCPROVER_1 — drop the ofdm pkt if the rx ofdm leg pkt fc version illegal
  [9] BIT_r_WMAC_PHYSTS_SNIF_1 — append sniff info after rxdesc
  [8] BIT_r_WMAC_PHYSTS_PLCP_1 — append plcp header after rxdesc
  [7] BIT_r_MAC_TCR_VBONF_RD_1 — vbon neg edge to read all data of mac rx sync fifo for rx parser
  [6] BIT_r_WMAC_TCR_MPAR_NDP_1 — nop ok check bb ndp vld & mac rx ndp check ok
  [5] BIT_r_WMAC_NDP_FILTER_1 — mac rx ndp pkt set ppdu len to 0
  [4] BIT_r_WMAC_RXLEN_SEL_1 — rx vht len sel lsig len VHT PPDU length selection 0: 收到VHT PPDU PKT 會根據 VHTSIGB PPDU length 來parsing 與計算 1: 收到VHT PPDU PKT 會根據 BB 算的 LSIG length 來parsing 與計算
  [3] BIT_r_WMAC_RXLEN_SEL1_1 — rx vht len sel lsig len if sigb len is more than lsig len
  [2] BIT_r_OFDM_FILTER_1 — RSVD
  [1] BIT_r_WMAC_CHK_OFDM_LEN_1 — enable to check ofdm len
  [0] BIT_r_WMAC_CHK_CCK_LEN_1 — enable to check rx cck len
0x7D8 REG_RX_FILTER_FUNCTION reset 0x30810041
  [31] BIT_RXHANG_EN — Force read error content from fifo to solve rxhang.
  [30] BIT_r_WMAC_MHRDDY_LATCH — Adjust mach_rdy timing if rx_parser and rxpktfifo FSM is not sync.
  [29] BIT_r_WMAC_MHRDDY_CLR — Reset mach_rdy_latch when rx parser begin parsing mac header.
  [28] BIT_r_RXPKTCTL_FSM_BASED_MPDURDY1 — Adjust mpdu_rdy timing to solve FSM behavier error.
  [27] BIT_WMAC_DIS_VHT_PLCP_CHK_MU — Disable check sigb crc value of MU plcp header.
  [26] BIT_r_CHK_DELIMIT_LEN — Drop mpdu if delimeter mpdu length smaller than mac header length + 4.
  [25] BIT_r_REAPTER_ADDR_MATCH — when this bit is set 1, physical address is matched when rx A1 is equal to tx A2, used in repeater mode
  [24] BIT_r_RXPKTCTL_FSM_BASED_MPDURDY — when this bit is set 1, rxpktfifo_ctl FSM jumps based on mpdu_valid(all MPDU data has been transferred to rxpktbuffer), when this bit is set 0, rxpktfifo_ctl FSM jumps based on fcs_valid(all MPDU data has been parsed by rx_parser)
  [23] BIT_r_LATCH_MACHRDY — when this bit set 1,mach_rdy signal is latched to make sure that rxpktfifo_ctl can detect it
  [22] BIT_r_WMAC_RXFIL_REND — when this bit set 1,icvmic_valid signal is cleared when icvmic_rdy is valid(ICV/MIC is parsed)
  [21] BIT_r_WMAC_MPDURDY_CLR — when the bit is set 1, the last MPDU which will be transferred to rxpktfifo is ready and error occurs, mpdu_rdy signal is also valid(is means all MPDU data has been transferred to rxpktbuffer)
  [20] BIT_r_WMAC_CLRRXSEC — If new rx pkt is coming, reset the previous rx key search result.
  [19] BIT_r_WMAC_RXFIL_RDEL — If new rx pkt is coming, reset the rxpkt_ctl FSM after parsing plcp.
  [18] BIT_r_WMAC_RXFIL_FCSE — If rx pkt is not ampdu and rejected, reset rxpkt_ctl FSM immediately after parsing header
  [17] BIT_r_WMAC_RXFIL_MESH_DEL — drop the ofdm pkt if the rx ofdm leg pkt fc type is 2'b11
  [16] BIT_r_WMAC_RXFIL_MASKM — drop the ofdm pkt if the rx ofdm leg pkt fc type is 2'b11
  [15:0] BIT_r_WMAC_RX_FIL_LEN_2 — use with BIT_r_WMAC_FIL_CTLPKTLEN
0x7E0 REG_WMAC_OPTION_FUNCTION_3 reset 0x5845A5
  [22] BIT_r_SIFS_ABORT_TB — sifs_reach check fcs fail abort tx tb option
  [21] BIT_r_WMAC_MORE_DATA — more data field in FC for ack/ba/mba
  [20:0] BIT_r_WMAC_TXNDP_SIGB — SIGB for NDP packet when BW =40MHz
0x7E4 REG_WMAC_DBG_SEL
  [10:8] BIT_TXCMD_DBG_SHIFT, [1:0] BIT_TXCMD_DBG_SEL
0x7E8 REG_WMAC_DBG_SHIFT ro
  [31:0] BIT_MACTX_CMD_SHIFT
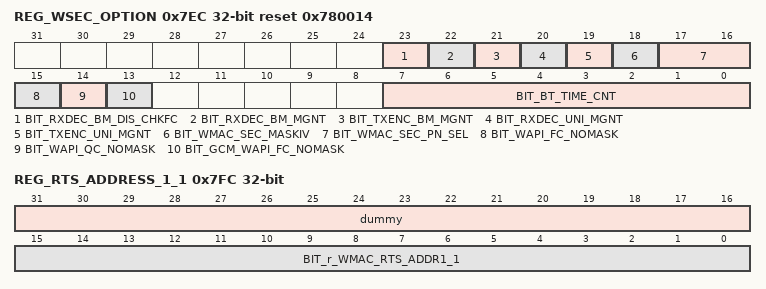
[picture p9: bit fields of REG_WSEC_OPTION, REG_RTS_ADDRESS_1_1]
0x7EC REG_WSEC_OPTION reset 0x780014
  [23] BIT_RXDEC_BM_DIS_CHKFC — disenable check fc[14] when bip decryption
  [22] BIT_RXDEC_BM_MGNT — decryption enable of rx multicast management pkt, 0x680[3] shall also be set valid
  [21] BIT_TXENC_BM_MGNT — encryption enable of tx multicast management pkt, 0x680[2] shall also be set valid
  [20] BIT_RXDEC_UNI_MGNT — decryption enable of rx unicast management pkt, 0x680[3] shall also be set valid
  [19] BIT_TXENC_UNI_MGNT — encryption enable of tx unicast management pkt, 0x680[2] shall also be set valid
  [18] BIT_WMAC_SEC_MASKIV — MASK IV[15:8] for GCMP security
  [17:16] BIT_WMAC_SEC_PN_SEL — Security GCMP header PN selection
  [15] BIT_WAPI_FC_NOMASK — If set to 1, enable old WAPI ADD format, don't mask FC bit4~6, bit8~15, If set to 0, enable new WAPI ADD format, mask FC bit15 to 0.
  [14] BIT_WAPI_QC_NOMASK — If set to 1, enable old WAPI ADD format, don't mask QC bit4~6, bit8~15, If set to 0, enable new WAPI ADD format, mask QC bit4~6, bit8~15 to 0.
  [13] BIT_GCM_WAPI_FC_NOMASK — If set to 1, enable old GCM-WAPI ADD format, don't mask FC bit4~6, bit8~15, If set to 0, enable new GCM-WAPI ADD format, mask FC bit15 to 0.
  [7:0] BIT_BT_TIME_CNT — US timer counter boundary of BTCOEXIST
0x7F0 REG_RTS_ADDRESS_0
  [31:0] BIT_r_WMAC_RTS_ADDR0 — if 0x604[31]=1 & rts is multicast, use this value as Address1 of RTS
0x7F4 REG_RTS_ADDRESS_0_1
  [15:0] BIT_r_WMAC_RTS_ADDR0_1 — if 0x604[31]=1 & rts is multicast, use this value as Address1 of RTS
0x7F8 REG_RTS_ADDRESS_1
  [31:0] BIT_r_WMAC_RTS_ADDR1 — if 0x604[31]=1 & rts is multicast, use this value as Address1 of RTS
0x7FC REG_RTS_ADDRESS_1_1
  [31:16] dummy
  [15:0] BIT_r_WMAC_RTS_ADDR1_1 — if 0x604[31]=1 & rts is multicast, use this value as Address1 of RTS
